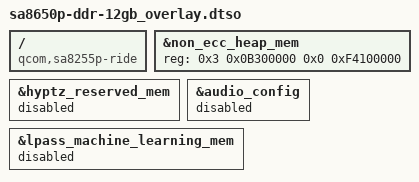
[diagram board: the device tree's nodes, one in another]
// SPDX-License-Identifier: BSD-3-Clause
/*
 * Copyright (c) Qualcomm Technologies, Inc. and/or its subsidiaries.
 */
/dts-v1/;
/plugin/;

/ {
	compatible = "qcom,sa8255p-ride";
};

&non_ecc_heap_mem {
	reg = <0x3 0x0B300000 0x0 0xF4100000>;
};

&hyptz_reserved_mem {
	status = "disabled";
};

&audio_config {
	status = "disabled";
};

&lpass_machine_learning_mem {
	status = "disabled";
};

